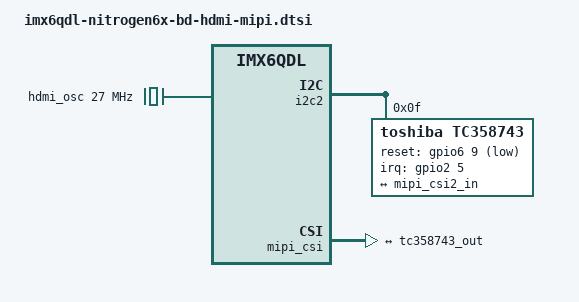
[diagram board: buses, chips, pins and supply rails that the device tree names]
/*
 * Copyright 2015 Philipp Zabel, Pengutronix
 *
 * The code contained herein is licensed under the GNU General Public
 * License. You may obtain a copy of the GNU General Public License
 * Version 2 or later at the following locations:
 *
 * http://www.opensource.org/licenses/gpl-license.html
 * http://www.gnu.org/copyleft/gpl.html
 */
#include <dt-bindings/gpio/gpio.h>
#include <dt-bindings/interrupt-controller/irq.h>

/ {
	hdmi_osc: hdmi-osc {
		compatible = "fixed-clock";
		clock-output-names = "hdmi-osc";
		clock-frequency = <27000000>;
		#clock-cells = <0>;
	};
};

&i2c2 {
	tc358743: tc358743@0f {
		compatible = "toshiba,tc358743";
		pinctrl-names = "default";
		pinctrl-0 = <&pinctrl_tc358743>;
		reg = <0x0f>;
		clocks = <&hdmi_osc>;
		clock-names = "refclk";
		reset-gpios = <&gpio6 9 GPIO_ACTIVE_LOW>;
		interrupt-parent = <&gpio2>;
		interrupts = <5 IRQ_TYPE_LEVEL_HIGH>;

		port@0 {
			tc358743_out: endpoint {
				remote-endpoint = <&mipi_csi2_in>;
				data-lanes = <1 2 3 4>;
				clock-lanes = <0>;
				clock-noncontinuous;
				link-frequencies = /bits/ 64 <297000000>;
			};
		};
	};
};

&iomuxc {
	pinctrl-names = "default";
	pinctrl-0 = <&pinctrl_hog>;

	imx6q-nitrogen6x-tc358743 {
		pinctrl_tc358743: tc358743grp {
			fsl,pins = <
				MX6QDL_PAD_NANDF_WP_B__GPIO6_IO09 0x4000b0b0	/* RESETN */
				MX6QDL_PAD_NANDF_D5__GPIO2_IO05   0x400130b0	/* INT */
			>;
		};
	};
};

&mipi_csi {
	status = "okay";

	port@0 {
		mipi_csi2_in: endpoint {
			remote-endpoint = <&tc358743_out>;
			data-lanes = <1 2 3 4>;
			clock-lanes = <0>;
			clock-noncontinuous;
			link-frequencies = /bits/ 64 <297000000>;
		};
	};
};
